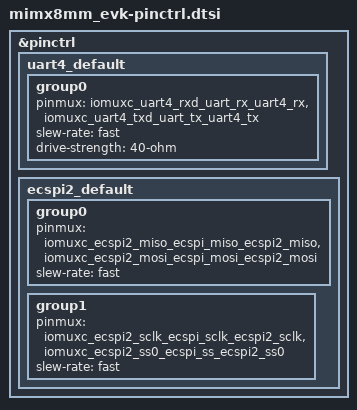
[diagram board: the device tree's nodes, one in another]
/*
 * Copyright (c) 2022, NXP
 * SPDX-License-Identifier: Apache-2.0
 *
 * Note: File generated by imx_cfg_utils.py
 * from MIMX8MM-EVK-REV-C.mex
 */

#include <nxp/nxp_imx/mimx8mm6dvtlz-pinctrl.dtsi>

&pinctrl {
	uart4_default: uart4_default {
		group0 {
			pinmux = <&iomuxc_uart4_rxd_uart_rx_uart4_rx>,
				<&iomuxc_uart4_txd_uart_tx_uart4_tx>;
			slew-rate = "fast";
			drive-strength = "40-ohm";
		};
	};

	ecspi2_default: ecspi2_default {
		group0 {
			pinmux = <&iomuxc_ecspi2_miso_ecspi_miso_ecspi2_miso>,
				<&iomuxc_ecspi2_mosi_ecspi_mosi_ecspi2_mosi>;
			slew-rate = "fast";
			/* TODO */
		};
		group1 {
			pinmux = <<&iomuxc_ecspi2_sclk_ecspi_sclk_ecspi2_sclk>,
				<&iomuxc_ecspi2_ss0_ecspi_ss_ecspi2_ss0>;
			slew-rate = "fast";
			/* TODO */
		};
	};
};
